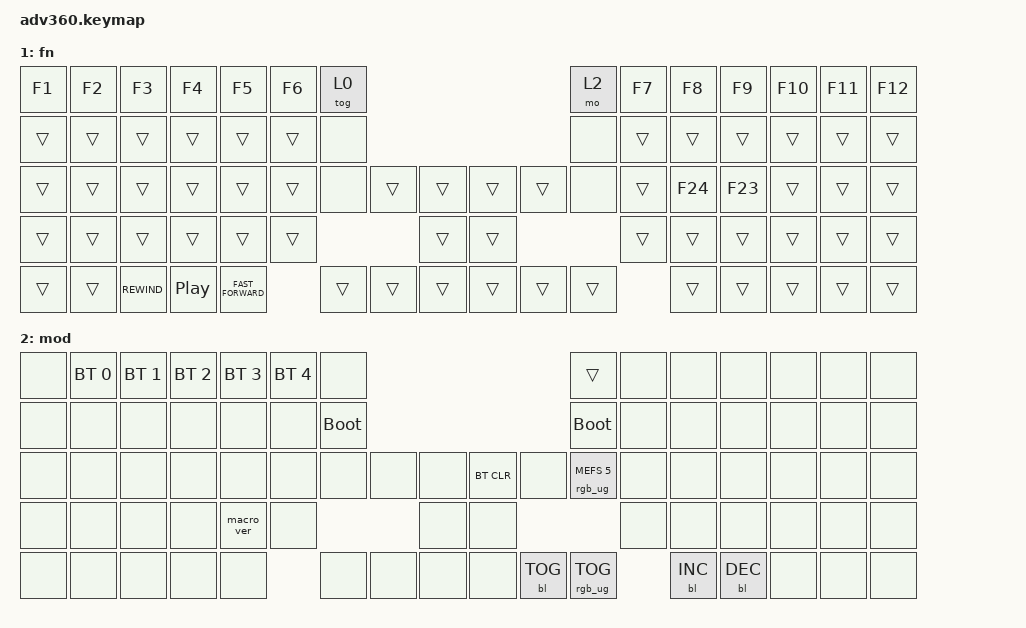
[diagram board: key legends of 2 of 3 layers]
#include <behaviors.dtsi>
#include <dt-bindings/zmk/backlight.h>
#include <dt-bindings/zmk/bt.h>
#include <dt-bindings/zmk/keys.h>
#include <dt-bindings/zmk/rgb.h>

/ {
    behaviors {
        #include "macros.dtsi"
      #include "version.dtsi"
      #ifndef VERSION_MACRO

        macro_ver: macro_ver {
            compatible = "zmk,behavior-macro";
            label = "macro_version";
            #binding-cells = <0>;
            bindings = <&kp RET>;
        };

        #endif

        hm: homerow_mods {
            compatible = "zmk,behavior-hold-tap";
            label = "HOMEROW_MODS";
            #binding-cells = <2>;
            tapping-term-ms = <200>;
            quick-tap-ms = <175>;
            flavor = "balanced";
            bindings = <&kp>, <&kp>;
        };

        pgrave: pipe_grave {
            compatible = "zmk,behavior-mod-morph";
            label = "pipe_grave";
            #binding-cells = <0>;
            bindings = <&kp PIPE>, <&kp GRAVE>;

            mods = <(MOD_LSFT|MOD_RSFT)>;
        };

        pkp_n1: plus_kp_n1 {
            compatible = "zmk,behavior-mod-morph";
            label = "plus_kp_n1";
            #binding-cells = <0>;
            bindings = <&kp PLUS>, <&kp N1>;

            mods = <(MOD_LSFT|MOD_RSFT)>;
        };

        lkp_n2: left_bracket_kp_n2 {
            compatible = "zmk,behavior-mod-morph";
            label = "left_bracket_kp_n2";
            bindings = <&kp LEFT_BRACKET>, <&kp N2>;

            #binding-cells = <0>;
            mods = <(MOD_LSFT|MOD_RSFT)>;
        };

        lkp_n3: left_brace_kp_n3 {
            compatible = "zmk,behavior-mod-morph";
            label = "left_brace_kp_n3";
            bindings = <&kp LEFT_BRACE>, <&kp N3>;

            #binding-cells = <0>;
            mods = <(MOD_LSFT|MOD_RSFT)>;
        };

        lkp_n4: left_parenthesis_kp_n4 {
            compatible = "zmk,behavior-mod-morph";
            label = "left_parenthesis_kp_n4";
            bindings = <&kp LEFT_PARENTHESIS>, <&kp N4>;

            #binding-cells = <0>;
            mods = <(MOD_LSFT|MOD_RSFT)>;
        };

        akp_5: amp_kp_n5 {
            compatible = "zmk,behavior-mod-morph";
            label = "amp_kp_n5";
            bindings = <&kp AMPERSAND>, <&kp N5>;

            #binding-cells = <0>;
            mods = <(MOD_LSFT|MOD_RSFT)>;
        };

        ekp_n6: equal_kp_n6 {
            compatible = "zmk,behavior-mod-morph";
            label = "equal_kp_n6";
            #binding-cells = <0>;
            bindings = <&kp EQUAL>, <&kp N6>;

            mods = <(MOD_LSFT|MOD_RSFT)>;
        };

        rkp_n7: right_parenthesis_kp_n7 {
            compatible = "zmk,behavior-mod-morph";
            label = "right_parenthesis_kp_n7";
            #binding-cells = <0>;
            bindings = <&kp RIGHT_PARENTHESIS>, <&kp N7>;

            mods = <(MOD_LSFT|MOD_RSFT)>;
        };

        rkp_n8: right_brace_kp_n8 {
            compatible = "zmk,behavior-mod-morph";
            label = "right_brace_kp_n8";
            #binding-cells = <0>;
            bindings = <&kp RIGHT_BRACE>, <&kp N8>;

            mods = <(MOD_LSFT|MOD_RSFT)>;
        };

        rkp_n9: right_bracket_kp_n9 {
            compatible = "zmk,behavior-mod-morph";
            label = "right_bracket_kp_n9";
            #binding-cells = <0>;
            bindings = <&kp RIGHT_BRACKET>, <&kp N9>;

            mods = <(MOD_LSFT|MOD_RSFT)>;
        };

        skp_n0: star_kp_n0 {
            compatible = "zmk,behavior-mod-morph";
            label = "star_kp_n0";
            #binding-cells = <0>;
            bindings = <&kp STAR>, <&kp N0>;

            mods = <(MOD_LSFT|MOD_RSFT)>;
        };

        eprcnt: excl_prcnt {
            compatible = "zmk,behavior-mod-morph";
            label = "excl_prcnt";
            #binding-cells = <0>;
            bindings = <&kp EXCL>, <&kp PRCNT>;

            mods = <(MOD_LSFT|MOD_RSFT)>;
        };

        dgrave: dllr_grave {
            compatible = "zmk,behavior-mod-morph";
            label = "dllr_grave";
            #binding-cells = <0>;
            bindings = <&kp DLLR>, <&kp TILDE>;

            mods = <(MOD_LSFT|MOD_RSFT)>;
        };

        bhash: bslh_hash {
            compatible = "zmk,behavior-mod-morph";
            label = "bslh_hash";
            #binding-cells = <0>;
            bindings = <&kp BSLH>, <&kp HASH>;

            mods = <(MOD_LSFT|MOD_RSFT)>;
        };

        acaret: at_caret {
            compatible = "zmk,behavior-mod-morph";
            label = "at_caret";
            #binding-cells = <0>;
            bindings = <&kp AT>, <&kp CARET>;

            mods = <(MOD_LSFT|MOD_RSFT)>;
        };
    };

    macros {
    };

    combos {
        compatible = "zmk,combos";

        Escape_Left {
            bindings = <&kp ESC>;
            key-positions = <32 31 30>;
        };

        Escape_Right {
            bindings = <&kp ESC>;
            key-positions = <41 42 43>;
        };

        Enter_Left {
            bindings = <&kp ENTER>;
            key-positions = <29 30 31 32>;
        };

        Enter_Right {
            bindings = <&kp ENTER>;
            key-positions = <44 43 42 41>;
        };
    };

    keymap {
        compatible = "zmk,keymap";

        default_layer {
            bindings = <
&pgrave     &pkp_n1           &lkp_n2      &lkp_n3         &lkp_n4     &akp_5  &kp C_VOL_UP                                                  &mo 2      &ekp_n6  &rkp_n7     &rkp_n8          &rkp_n9      &skp_n0            &eprcnt
&kp TAB     &kp SEMI          &kp COMMA    &kp PERIOD      &kp P       &kp Y   &kp C_VOL_DN                                                  &none      &kp F    &kp G       &kp C            &kp R        &kp L              &bhash
&kp LGUI    &kp A  &kp O  &kp E  &kp UI U  &kp I   &kp C_MUTE    &kp LCTRL   &kp LGUI      &kp RGUI   &kp RALT   &none      &kp D    &kp H  &kp T_ALT T  &kp N  &kp S  &kp MINUS
&kp LSHIFT  &kp SQT           &kp Q        &kp J           &kp K       &kp X                             &kp ESC       &kp PG_UP                        &kp B    &kp M       &kp W            &kp V        &kp Z              &kp RSHFT
&mo 1       &dgrave           &kp CAPS     &kp LEFT        &kp RIGHT           &kp BSPC      &kp LSHIFT  &kp END       &kp PG_DN  &kp ENTER  &kp SPACE           &kp UP      &kp DOWN         &kp SLASH    &acaret            &mo 1
            >;
        };

        fn {
            bindings = <
&kp F1  &kp F2  &kp F3        &kp F4            &kp F5              &kp F6  &tog 0                                      &mo 2   &kp F7  &kp F8   &kp F9   &kp F10  &kp F11  &kp F12
&trans  &trans  &trans        &trans            &trans              &trans  &none                                       &none   &trans  &trans   &trans   &trans   &trans   &trans
&trans  &trans  &trans        &trans            &trans              &trans  &none   &trans  &trans      &trans  &trans  &none   &trans  &kp F24  &kp F23  &trans   &trans   &trans
&trans  &trans  &trans        &trans            &trans              &trans                  &trans      &trans                  &trans  &trans   &trans   &trans   &trans   &trans
&trans  &trans  &kp C_REWIND  &kp C_PLAY_PAUSE  &kp C_FAST_FORWARD          &trans  &trans  &trans      &trans  &trans  &trans          &trans   &trans   &trans   &trans   &trans
            >;
        };

        mod {
            bindings = <
&none  &bt BT_SEL 0  &bt BT_SEL 1  &bt BT_SEL 2  &bt BT_SEL 3  &bt BT_SEL 4  &none                                                  &trans                  &none  &none       &none       &none  &none  &none
&none  &none         &none         &none         &none         &none         &bootloader                                            &bootloader             &none  &none       &none       &none  &none  &none
&none  &none         &none         &none         &none         &none         &none        &none  &none      &bt BT_CLR  &none       &rgb_ug RGB_MEFS_CMD 5  &none  &none       &none       &none  &none  &none
&none  &none         &none         &none         &macro_ver    &none                             &none      &none                                           &none  &none       &none       &none  &none  &none
&none  &none         &none         &none         &none                       &none        &none  &none      &none       &bl BL_TOG  &rgb_ug RGB_TOG                &bl BL_INC  &bl BL_DEC  &none  &none  &none
            >;
        };
    };
};

/*test*/
